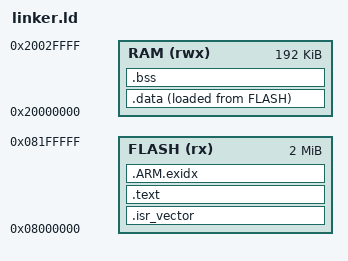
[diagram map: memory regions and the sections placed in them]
/* STM32F429ZIT6: 2 MiB flash and 192 KiB contiguous SRAM. */
ENTRY(Reset_Handler)

MEMORY
{
    FLASH (rx)  : ORIGIN = 0x08000000, LENGTH = 2048K
    RAM   (rwx) : ORIGIN = 0x20000000, LENGTH = 192K
}

_estack = ORIGIN(RAM) + LENGTH(RAM);

SECTIONS
{
    .isr_vector :
    {
        . = ALIGN(4);
        KEEP(*(.isr_vector))
        . = ALIGN(4);
    } > FLASH

    .text :
    {
        *(.text .text.*)
        *(.rodata .rodata.*)
        *(.ARM.extab* .gnu.linkonce.armextab.*)
        . = ALIGN(4);
    } > FLASH

    .ARM.exidx :
    {
        *(.ARM.exidx* .gnu.linkonce.armexidx.*)
        . = ALIGN(4);
    } > FLASH

    _sidata = LOADADDR(.data);
    .data :
    {
        . = ALIGN(4);
        _sdata = .;
        *(.data .data.*)
        . = ALIGN(4);
        _edata = .;
    } > RAM AT > FLASH

    .bss (NOLOAD) :
    {
        . = ALIGN(4);
        _sbss = .;
        *(.bss .bss.*)
        *(COMMON)
        . = ALIGN(4);
        _ebss = .;
    } > RAM
}
